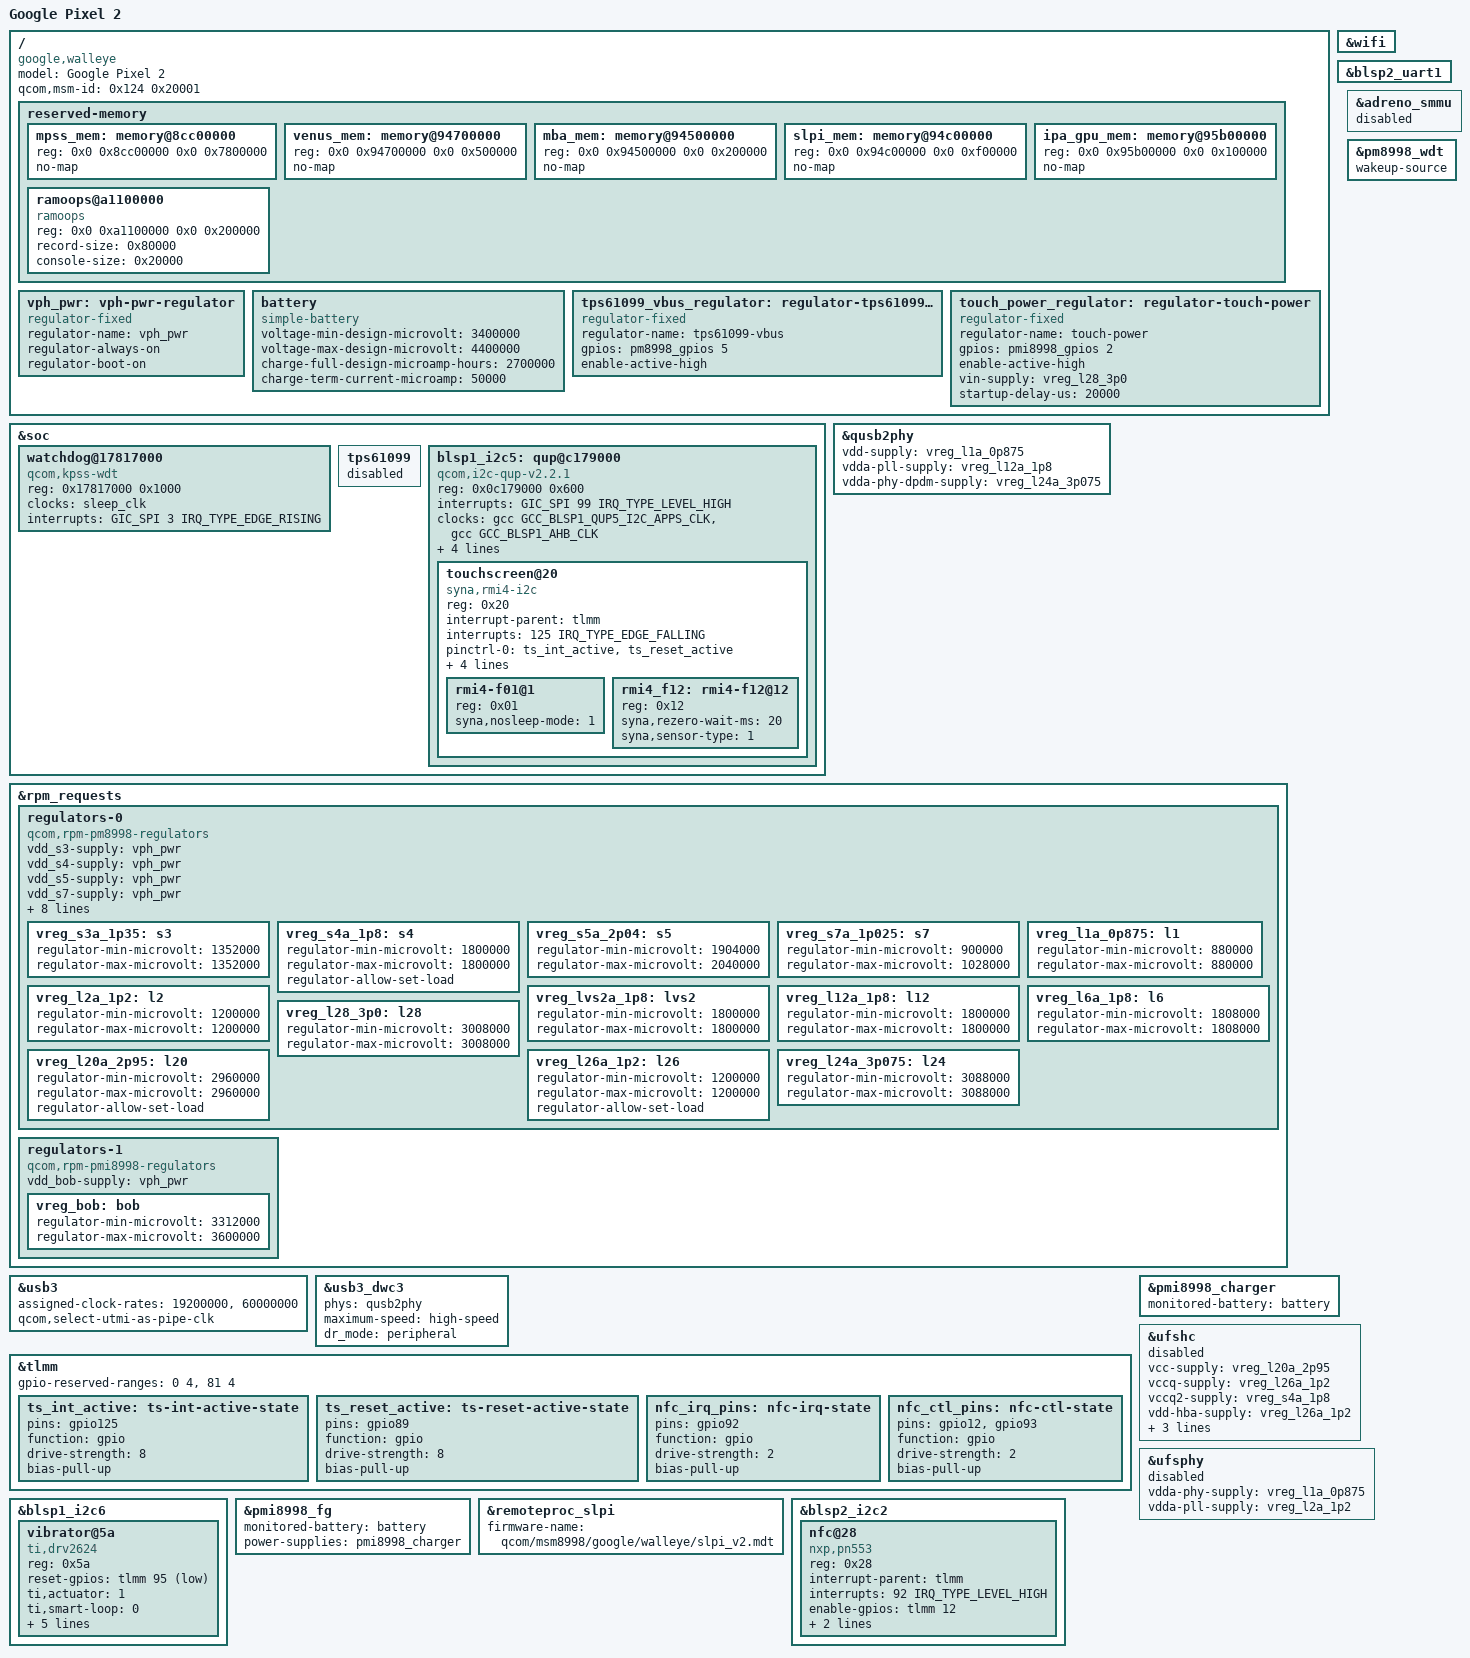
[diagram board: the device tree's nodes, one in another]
// SPDX-License-Identifier: GPL-2.0-only
/*
 * Google Pixel 2 (walleye) - the first mainline board file: only what a boot without a display needs.
 *
 * It brings up the SoC, its reserved memory, the RPM regulators the USB 2.0 PHY stands on, the USB
 * controller as a high-speed peripheral (the gadget is the first sign of life), pstore/ramoops and the
 * debug UART. Storage (UFS), display, GPU, Wi-Fi and the remote processors but the sensor hub (SLPI) stay off
 * until a part is brought up on purpose. The PMICs' SPMI nodes (mainline's pm8998.dtsi and pmi8998.dtsi) are in: their children bind or defer on their own.
 *
 * No /chosen/bootargs and no stdout-path: the bootloader appends the boot image's command line to the
 * device tree, and a bootargs already there would hide it (decision 2026-11-17-walleye-first-kernel).
 *
 * Derived, with their licences and authors kept, from the GPL wahoo board files of
 *   Copyright (c) 2020 Caleb Connolly <caleb@connolly.tech>   (kcxt/linux-wahoo, wahoo/5.17)
 * and, for the regulator and USB nodes, from mainline's OnePlus 5(T) common file
 *   Copyright (c) 2021, Jami Kettunen <jamipkettunen@gmail.com>
 *   Copyright (c) 2016, The Linux Foundation. All rights reserved.
 * The regulator limits and the modem carve-out are the values of that GPL wahoo file; the mba, video, sensor-hub and ipa/gpu carve-outs are the phone's running ones (below)
 * (the downstream sources are kerneltoast/android_kernel_google_wahoo, arch/arm64/boot/dts/htc).
 * Nothing here comes from a proprietary source (decision walleye-input-wall).
 */

/dts-v1/;

#include "msm8998.dtsi"
#include "pm8998.dtsi"
#include "pmi8998.dtsi"
/*
 * Overlay collisions (tests/host/overlay-collisions.sh, decision 2026-11-19-walleye-overlay-collisions-as-a-class): the bootloader merges the vendor dtbo overlay
 * into the dtb BY NAME - a node of the overlay with the name of a node of ours, or a fragment that targets one of our labels, overwrites its properties. So a node the
 * overlay writes must not be ours: mainline's PCIe host (disabled here; the overlay's pcie0 fragment writes its reg and ranges) is dropped and its label is a stub, and
 * the QUP i2c controller of the touch panel is named qup@c179000 (below), not i2c@c179000 (z16).
 */
/delete-node/ &pcie0;

#include "msm8998-google-walleye-overlay-stubs.dtsi"

/delete-node/ &mpss_mem;
/delete-node/ &venus_mem;
/delete-node/ &mba_mem;
/delete-node/ &slpi_mem;

/*
 * The running layout of the phone (decision 2026-11-23-walleye-slpi-carveout-running-layout, research walleye-slpi-carveout-read): the SLPI image needs one
 * 15 MiB block, which the phone's own dtbo and running fdt put at 0x94c00000; that range swallows mainline's four ipa/gpu/wlan nodes, which go (the wifi node,
 * disabled here, names wlan_msa_mem, so it drops that property: dtc refuses a reference to a deleted node), and the phone's 0x95b00000/1 MiB ipa/gpu block takes their place.
 */
&wifi {
	/delete-property/ memory-region;
};

/delete-node/ &ipa_fw_mem;
/delete-node/ &ipa_gsi_mem;
/delete-node/ &gpu_mem;
/delete-node/ &wlan_msa_mem;

/ {
	model = "Google Pixel 2";
	compatible = "google,walleye", "google,wahoo", "qcom,msm8998";

	/* Required for the bootloader to select this device tree: 8998 v2.1 (taimen has the same) */
	qcom,msm-id = <0x124 0x20001>;

	reserved-memory {
		/* The phone's running layout of the modem, video, MBA and sensor-hub regions (only the sensor hub is used here) */
		mpss_mem: memory@8cc00000 {
			reg = <0x0 0x8cc00000 0x0 0x7800000>;
			no-map;
		};

		venus_mem: memory@94700000 {
			reg = <0x0 0x94700000 0x0 0x500000>;
			no-map;
		};

		mba_mem: memory@94500000 {
			reg = <0x0 0x94500000 0x0 0x200000>;
			no-map;
		};

		slpi_mem: memory@94c00000 {
			reg = <0x0 0x94c00000 0x0 0xf00000>;
			no-map;
		};

		/* The phone's running layout's ipa/gpu block (0x95b00000, 1 MiB: the running fdt and the dtbo's pil_ipa_gpu_mem); the dtbo overlay writes its own pil_ipa_gpu_mem stub, not this node */
		ipa_gpu_mem: memory@95b00000 {
			reg = <0x0 0x95b00000 0x0 0x100000>;
			no-map;
		};

		/* The phone's own ramoops region (stock: 0xa1100000, 2 MiB, record 0x80000, console 0x20000, no pmsg): the stock system reads our kernel's log back after a warm reset */
		ramoops@a1100000 {
			compatible = "ramoops";
			reg = <0x0 0xa1100000 0x0 0x200000>;
			record-size = <0x80000>;
			console-size = <0x20000>;
		};
	};

	vph_pwr: vph-pwr-regulator {
		compatible = "regulator-fixed";
		regulator-name = "vph_pwr";
		regulator-always-on;
		regulator-boot-on;
	};
};

/*
 * The apps-processor (SoC) watchdog: msm8998.dtsi has none. Address and bark interrupt (SPI 3) are the downstream
 * MSM8998 values (wdog 0x17817000), NOT measured on this phone yet. The mainline-light init opens /dev/watchdog and
 * never pets it, so the SoC resets the phone by itself (the try's way back without hands). Decision
 * 2026-11-17-walleye-try-returns-without-hands.
 */
&soc {
	watchdog@17817000 {
		compatible = "qcom,kpss-wdt";
		reg = <0x17817000 0x1000>;
		clocks = <&sleep_clk>;
		interrupts = <GIC_SPI 3 IRQ_TYPE_EDGE_RISING>;
	};
};

/* The debug UART (the Pixel debug cable): earlycon=msm_serial_dm,0xc1b0000 */
&blsp2_uart1 {
	status = "okay";
};

&qusb2phy {
	status = "okay";

	vdd-supply = <&vreg_l1a_0p875>;
	vdda-pll-supply = <&vreg_l12a_1p8>;
	vdda-phy-dpdm-supply = <&vreg_l24a_3p075>;
};

/* The rails the USB 2.0 PHY stands on, and the rails those hang from */
&rpm_requests {
	regulators-0 {
		compatible = "qcom,rpm-pm8998-regulators";

		vdd_s3-supply = <&vph_pwr>;
		vdd_s4-supply = <&vph_pwr>;
		vdd_s5-supply = <&vph_pwr>;
		vdd_s7-supply = <&vph_pwr>;
		vdd_l1_l27-supply = <&vreg_s7a_1p025>;
		vdd_l2_l8_l17-supply = <&vreg_s3a_1p35>;
		vdd_l6-supply = <&vreg_s5a_2p04>;
		vdd_l7_l12_l14_l15-supply = <&vreg_s5a_2p04>;
		vdd_l20_l24-supply = <&vreg_bob>;
		vdd_l26-supply = <&vreg_s3a_1p35>;
		vdd_l16_l28-supply = <&vreg_bob>;
		vdd_lvs1_lvs2-supply = <&vreg_s4a_1p8>;

		vreg_s3a_1p35: s3 {
			regulator-min-microvolt = <1352000>;
			regulator-max-microvolt = <1352000>;
		};

		vreg_s4a_1p8: s4 {
			regulator-min-microvolt = <1800000>;
			regulator-max-microvolt = <1800000>;
			regulator-allow-set-load;
		};

		vreg_s5a_2p04: s5 {
			regulator-min-microvolt = <1904000>;
			regulator-max-microvolt = <2040000>;
		};

		vreg_s7a_1p025: s7 {
			regulator-min-microvolt = <900000>;
			regulator-max-microvolt = <1028000>;
		};

		vreg_l1a_0p875: l1 {
			regulator-min-microvolt = <880000>;
			regulator-max-microvolt = <880000>;
		};

		/* msm8998.dtsi names these rails for the display PHY and the sensor hub (both off here); l2 also feeds the UFS phy PLL */
		vreg_l2a_1p2: l2 {
			regulator-min-microvolt = <1200000>;
			regulator-max-microvolt = <1200000>;
		};

		vreg_lvs2a_1p8: lvs2 {
			regulator-min-microvolt = <1800000>;
			regulator-max-microvolt = <1800000>;
		};

		vreg_l12a_1p8: l12 {
			regulator-min-microvolt = <1800000>;
			regulator-max-microvolt = <1800000>;
		};

		/* The touch panel's rails (item walleye-touch-rmi4): l6 its I/O, l28 its supply, the OnePlus 5's values */
		vreg_l6a_1p8: l6 {
			regulator-min-microvolt = <1808000>;
			regulator-max-microvolt = <1808000>;
		};

		vreg_l28_3p0: l28 {
			regulator-min-microvolt = <3008000>;
			regulator-max-microvolt = <3008000>;
		};

		/* UFS rails (item walleye-ufs-readonly): VCC from l20, VCCQ and the host adapter from l26, as the OnePlus 5 and the wahoo GPL tree */
		vreg_l20a_2p95: l20 {
			regulator-min-microvolt = <2960000>;
			regulator-max-microvolt = <2960000>;
			regulator-allow-set-load;
		};

		vreg_l26a_1p2: l26 {
			regulator-min-microvolt = <1200000>;
			regulator-max-microvolt = <1200000>;
			regulator-allow-set-load;
		};

		vreg_l24a_3p075: l24 {
			regulator-min-microvolt = <3088000>;
			regulator-max-microvolt = <3088000>;
		};
	};

	regulators-1 {
		compatible = "qcom,rpm-pmi8998-regulators";

		vdd_bob-supply = <&vph_pwr>;

		vreg_bob: bob {
			regulator-min-microvolt = <3312000>;
			regulator-max-microvolt = <3600000>;
		};
	};
};

/*
 * The type-C port is USB 3 capable, but the SuperSpeed PHY is dropped: Google's wahoo boards (kcxt,
 * porthole) only got the gadget up at USB 2.0 speed.
 */
&usb3 {
	status = "okay";

	/* Operate "GCC_USB30_MASTER_CLK" in HS mode (>= 60 MHz) */
	assigned-clock-rates = <19200000>, <60000000>;

	/* Disable the USB3 pipe_clk requirement */
	qcom,select-utmi-as-pipe-clk;
};

&usb3_dwc3 {
	/* Drop the USB 3 PHY */
	phys = <&qusb2phy>;
	phy-names = "usb2-phy";

	maximum-speed = "high-speed";

	/* Peripheral until the type-C port is hooked up */
	dr_mode = "peripheral";
};

&tlmm {
	/*
	 * GPIOs 0-3 and 81-84 are expected to belong to the secure world (TrustZone); touching them from
	 * the non-secure side is expected to reset the phone (the mechanism is inferred, not measured here).
	 * Source: the alive taimen dtb and porthole's walleye dtb carry exactly this property, and the fdt
	 * bisect (research walleye-fdt-bisect-x-tried) showed that taking it out of the alive tree kills init
	 * twice (x1): its absence is a cause of dead dtbs of ours; image y1 tests whether adding it is enough.
	 * The vendor kernel's running fdt has no such property (its driver never touches those pins).
	 */
	gpio-reserved-ranges = <0 4>, <81 4>;
};

/*
 * The charger (item walleye-charger-smb2): pmi8998's SMB2 charger (qcom_smbx), its USB-input current and voltage read by
 * the PMIC's own round-robin ADC (pmi8998.dtsi has both nodes; the charger is disabled there). The driver sets the float
 * voltage from voltage-max-design and refuses to probe without a monitored battery. Cell facts are the vendor GPL tree's
 * (kerneltoast/android_kernel_google_wahoo): 2700 mAh, 4.4 V max, 3.4 V cutoff, 50 mA termination. The charge level
 * level comes from the fuel gauge below (item walleye-fuel-gauge).
 */
&pmi8998_charger {
	monitored-battery = <&battery>;
	status = "okay";
};

/ {
	battery: battery {
		compatible = "simple-battery";
		voltage-min-design-microvolt = <3400000>;
		voltage-max-design-microvolt = <4400000>;
		charge-full-design-microamp-hours = <2700000>;
		charge-term-current-microamp = <50000>;
	};
};

/*
 * The GPU's smmu stays off until GPU work (item walleye-dmesg-clean, research walleye-z6-dmesg-mapped G1): its power domain is
 * gpucc's GPU_GX_GDSC, which cannot switch on without a GFX rail nothing in this dts powers (which rail: not known yet). Left on, it
 * logs six "gpu_gx status stuck" WARNs, defers for ever and holds gcc's and gpucc's sync_state.
 */
&adreno_smmu {
	status = "disabled";
};

/*
 * The PMIC's own watchdog (item walleye-kernel-pmic-wdt, linux-phone-oco/linux topic/pmic-wdt-wake-in-suspend on v7.3): pm8998.dtsi describes it, in the series
 * (qcom,pm8998-wdt, bite interrupt) and leaves it disabled. Enabled with wakeup-source, the driver keeps it running through
 * suspend, so a bite is a way to wake the phone (proof pmic-wdt-bites, pmic-wdt-wakes-in-suspend).
 */
&pm8998_wdt {
	wakeup-source;
	status = "okay";
};

/*
 * The charger's boost supply (item walleye-charger-supplier, decision 2026-11-18-walleye-charger-supplier-permissive-then-modelled).
 * Read from the phone's running fdt (vfa try): the TI TPS61099 boost converter is switched by one PMIC pin, pm8998 gpio 5
 * (active high), and makes the rail "tps61099-vbus"; the vendor dtbo overlay adds /soc@0/tps61099 (compatible ti,tps61099,
 * no mainline driver) and points the charger's external-vbus-supply at its child. That unbound device was the supplier c2's
 * charger waited on. The board's part is modelled here as what it is for the kernel: a fixed regulator on that pin, off until
 * something asks for it (nothing does yet).
 * The overlay's merge overwrites a compatible set on its own node, so the regulator cannot sit at /soc@0/tps61099: it is a node
 * of ours, and the overlay's driverless copy is marked disabled (the overlay sets no status), which fw_devlink does not wait on
 * (of_link_to_phandle: a supplier whose node is unavailable gets no link).
 */
/ {
	tps61099_vbus_regulator: regulator-tps61099-vbus {
		compatible = "regulator-fixed";
		regulator-name = "tps61099-vbus";
		gpios = <&pm8998_gpios 5 GPIO_ACTIVE_HIGH>;
		enable-active-high;
	};
};

&soc {
	tps61099 {
		status = "disabled";
	};
};

/*
 * The UFS storage is OFF (decision 2026-11-19-walleye-ufs-off-by-a-gate; research walleye-ufs-on-by-accident): it was on in every image from z11 and was probed
 * against the author's word. No image of ours boots with it on: tests/host/ufs-off-image.sh gates every boot image. The nodes keep the OnePlus 5's rails (same SoC,
 * same RPM regulators: l20 2.96 V vcc, l26 1.2 V vccq and hba, s4 1.8 V vccq2; phy l1 and l2), so dt/msm8998-google-walleye-ufs.dts, the variant of the z11-z13
 * experiments, only flips the status. Sony's yoshino keeps UFS off for a card that needs quirks before it is probed (msm8998-sony-xperia-yoshino.dtsi); which card is
 * in the phone is not known yet.
 */
&ufshc {
	status = "disabled";

	vcc-supply = <&vreg_l20a_2p95>;
	vccq-supply = <&vreg_l26a_1p2>;
	vccq2-supply = <&vreg_s4a_1p8>;
	vdd-hba-supply = <&vreg_l26a_1p2>;
	vcc-max-microamp = <750000>;
	vccq-max-microamp = <560000>;
	vccq2-max-microamp = <750000>;
};

&ufsphy {
	status = "disabled";

	vdda-phy-supply = <&vreg_l1a_0p875>;
	vdda-pll-supply = <&vreg_l2a_1p2>;
};

/*
 * The touch panel (item walleye-touch-rmi4): a Synaptics RMI4 touch controller on blsp1_i2c5 at 0x20, interrupt gpio125, reset gpio89 -
 * the pins and the address of the wahoo GPL tree and of mainline's OnePlus 5 (same SoC), which uses the same mainline rmi_i2c driver.
 * The rails are pm8998 l6 (1.8 V I/O) and l28 (3.0 V); the phone's own dtbo overlay (entry 3) adds a pmi8998 power gpio, gpio 2 active high
 * (synaptics,power-gpio, power-on-state 1), modelled below as a fixed regulator the touch node takes as vdd (item walleye-build-z17-touch-power; z16 left it
 * undriven and the chip was silent). The overlay's switch-gpio (tlmm gpio 75) is not known yet. The panel size is not known yet either (touchscreen-x-mm/y-mm left out: the driver reads
 * the sensor's own size); the display stays off, so the test is a person's touch read as events.
 */
&tlmm {
	ts_int_active: ts-int-active-state {
		pins = "gpio125";
		function = "gpio";
		drive-strength = <8>;
		bias-pull-up;
	};

	ts_reset_active: ts-reset-active-state {
		pins = "gpio89";
		function = "gpio";
		drive-strength = <8>;
		bias-pull-up;
	};
};

/ {
	touch_power_regulator: regulator-touch-power {
		compatible = "regulator-fixed";
		regulator-name = "touch-power";
		gpios = <&pmi8998_gpios 2 GPIO_ACTIVE_HIGH>;
		enable-active-high;
		vin-supply = <&vreg_l28_3p0>;
		startup-delay-us = <20000>;
	};
};

/* The QUP i2c controller of mainline's msm8998.dtsi, under the name qup@c179000: the overlay's own i2c@c179000 must not merge into it (z16). Label, reg, everything else unchanged. */
/delete-node/ &blsp1_i2c5;

&soc {
	blsp1_i2c5: qup@c179000 {
		compatible = "qcom,i2c-qup-v2.2.1";
		reg = <0x0c179000 0x600>;
		interrupts = <GIC_SPI 99 IRQ_TYPE_LEVEL_HIGH>;

		clocks = <&gcc GCC_BLSP1_QUP5_I2C_APPS_CLK>,
			 <&gcc GCC_BLSP1_AHB_CLK>;
		clock-names = "core", "iface";
		dmas = <&blsp1_dma 14>, <&blsp1_dma 15>;
		dma-names = "tx", "rx";
		pinctrl-names = "default", "sleep";
		pinctrl-0 = <&blsp1_i2c5_default>;
		pinctrl-1 = <&blsp1_i2c5_sleep>;
		clock-frequency = <400000>;

		status = "disabled";
		#address-cells = <1>;
		#size-cells = <0>;
	};
};

&blsp1_i2c5 {
	status = "okay";

	touchscreen@20 {
		compatible = "syna,rmi4-i2c";
		reg = <0x20>;
		#address-cells = <1>;
		#size-cells = <0>;

		interrupt-parent = <&tlmm>;
		interrupts = <125 IRQ_TYPE_EDGE_FALLING>;

		pinctrl-names = "default";
		pinctrl-0 = <&ts_int_active &ts_reset_active>;

		vdd-supply = <&touch_power_regulator>;
		vio-supply = <&vreg_l6a_1p8>;

		syna,reset-delay-ms = <20>;
		syna,startup-delay-ms = <20>;

		rmi4-f01@1 {
			reg = <0x01>;
			syna,nosleep-mode = <1>;
		};

		rmi4_f12: rmi4-f12@12 {
			reg = <0x12>;
			syna,rezero-wait-ms = <20>;
			syna,sensor-type = <1>;
		};
	};
};

/*
 * The vibration motor (item walleye-drv2624-driver): a TI DRV2624 on QUP6's i2c at 0x5a, its nRESET on gpio95, an LRA of 155 Hz. The values are the stock
 * overlay's own (fragment i2c_6: ti,rated-voltage 0x4d = 77, ti,odclamp-voltage 0xa5 = 165, ti,lra-frequency 0x9b = 155, closed loop, square wave), the same
 * as porthole's taimen node. The overlay's fragments target the label i2c_6, which is a stub here, so its drv2624@5a lands in the stub and not on this node.
 * The driver is not in mainline (kernel/drv2624/, with its binding).
 */
&blsp1_i2c6 {
	status = "okay";

	vibrator@5a {
		compatible = "ti,drv2624";
		reg = <0x5a>;

		reset-gpios = <&tlmm 95 GPIO_ACTIVE_LOW>;

		ti,actuator = <1>;		/* LRA */
		ti,smart-loop = <0>;		/* closed loop */
		ti,rated-voltage = <77>;
		ti,odclamp-voltage = <165>;
		ti,lra-frequency = <155>;	/* f0 = 155 Hz */
		ti,ol-lra-frequency = <155>;
		ti,lra-wave-shape = <0>;	/* square */
	};
};

/*
 * The fuel gauge (item walleye-fuel-gauge): pmi8998's FG gen3 reads the cell's charge level, voltage and current; the driver (power: supply: pmi8998_fg,
 * RFC v1 of 2025-11-24 by David Heidelberg, driver by Joel Selvaraj, node by Casey Connolly: not in mainline) is carried as patch files in this build only.
 * The node is the series' own (pmi8998.dtsi, disabled); here it is enabled with the cell above and the charger as its status source. The driver
 * reads the charge level the gauge computed (the gauge's firmware profile stays in the PMIC), so the cell's design numbers are the binding's, not a table of ours.
 */
&pmi8998_fg {
	monitored-battery = <&battery>;
	power-supplies = <&pmi8998_charger>;
	status = "okay";
};

/*
 * The sensor hub (SLPI) with the phone's own firmware, loaded from the rootfs or ramdisk (item walleye-slpi-carveout-dts; decision 2026-11-23-walleye-slpi-carveout-running-layout).
 * The rest of the node is mainline's (pas id 12, smp2p-slpi, glink edge "dsps", px = lvs2, cx = SSCCX). NOT KNOWN YET: reg is mainline's 0x5800000, the phone's own node says
 * 0x5c00000 (research walleye-slpi-carveout-read); the pas driver does not touch the registers it maps (TZ owns the reset), so it is left as mainline has it. The smallest
 * try that answers it is the boot of this image with remoteproc_slpi to "running" (item walleye-slpi-boot-qrtr): if it starts, the reg did not matter; if the start fails, set reg
 * to <0x05c00000 0x4040> and try once more.
 */
&remoteproc_slpi {
	firmware-name = "qcom/msm8998/google/walleye/slpi_v2.mdt";
	status = "okay";
};

/*
 * The NFC controller (item walleye-nfc-dts-node-image): the Pixel 2's NXP PN553 (Android's node nq@28, compatible qcom,nq-nci, on its i2c@c1b6000, which is mainline's blsp2_i2c2:
 * gpio6/7, function blsp_i2c8, the address c1b6000 read from msm8998.dtsi). Pins as Android's dtb has them (research walleye-nfc-android-dtb-read): interrupt gpio92 (level high),
 * enable (nq-ven) gpio12, firmware download (nq-firm) gpio93. Android's nfc_active pulls gpio12, gpio92 and gpio116 up; gpio116's role was not read, so it is not set here.
 * The mainline driver (nxp-nci, binding nxp,nci: nxp,pn553 then nxp,nxp-nci-i2c) takes no clock and no supply. NOT KNOWN YET: the controller's clock (Android: BBCLK3, clkreq on
 * pm8998 gpio21; the image's command line has clk_ignore_unused, so a clock the bootloader left on stays on), the pins' drive strength (2 mA is the common value of this dtsi, not read),
 * and the eSE's pins (nq-esepwr gpio30, nq-clear_n gpio29, the eSE on spi, gpio2): the secure element is out of reach and left out. If nxp-nci does not probe, the clock is the first thing to read.
 */
&tlmm {
	nfc_irq_pins: nfc-irq-state {
		pins = "gpio92";
		function = "gpio";
		drive-strength = <2>;
		bias-pull-up;
	};

	nfc_ctl_pins: nfc-ctl-state {
		pins = "gpio12", "gpio93";
		function = "gpio";
		drive-strength = <2>;
		bias-pull-up;
	};
};

&blsp2_i2c2 {
	status = "okay";

	nfc@28 {
		compatible = "nxp,pn553", "nxp,nxp-nci-i2c";
		reg = <0x28>;

		interrupt-parent = <&tlmm>;
		interrupts = <92 IRQ_TYPE_LEVEL_HIGH>;

		enable-gpios = <&tlmm 12 GPIO_ACTIVE_HIGH>;
		firmware-gpios = <&tlmm 93 GPIO_ACTIVE_HIGH>;

		pinctrl-names = "default";
		pinctrl-0 = <&nfc_irq_pins &nfc_ctl_pins>;
	};
};
